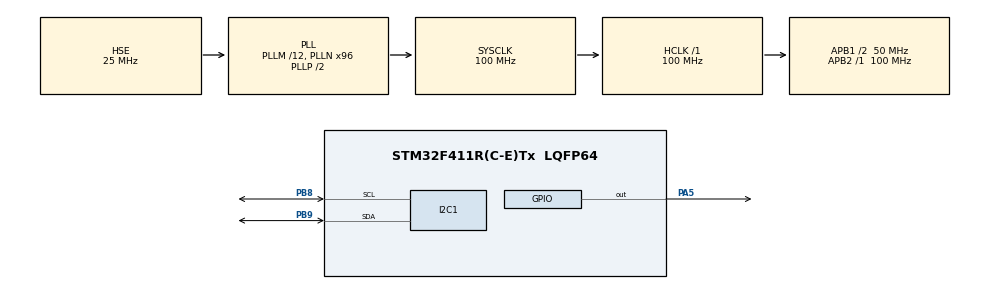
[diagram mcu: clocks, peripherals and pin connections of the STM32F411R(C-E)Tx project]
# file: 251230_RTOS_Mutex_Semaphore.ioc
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FREERTOS.BinarySemaphores01=lcdBinarySem,Dynamic,NULL,Available
FREERTOS.Mutexes01=lcdMutex,Dynamic,NULL,Available
FREERTOS.Tasks01=defaultTask,0,128,StartDefaultTask,Default,NULL,Dynamic,NULL,NULL;myTask02,0,128,StartTask02,Default,NULL,Dynamic,NULL,NULL;myTask03,0,128,StartTask03,Default,NULL,Dynamic,NULL,NULL
FREERTOS.configUSE_NEWLIB_REENTRANT=1
Mcu.Family=STM32F4
Mcu.Name=STM32F411R(C-E)Tx
Mcu.Package=LQFP64
NVIC.PriorityGroup=NVIC_PRIORITYGROUP_4
NVIC.TIM1_TRG_COM_TIM11_IRQn=true\:15\:0\:false\:false\:true\:false\:false\:true\:true
NVIC.TimeBase=TIM1_TRG_COM_TIM11_IRQn
NVIC.TimeBaseIP=TIM11
PA13.Mode=Serial_Wire
PA13.Signal=SYS_JTMS-SWDIO
PA14.Mode=Serial_Wire
PA14.Signal=SYS_JTCK-SWCLK
PA5.Signal=GPIO_Output
PB8.Mode=I2C
PB8.Signal=I2C1_SCL
PB9.Mode=I2C
PB9.Signal=I2C1_SDA
PH0\ -\ OSC_IN.Mode=HSE-External-Oscillator
PH0\ -\ OSC_IN.Signal=RCC_OSC_IN
PH1\ -\ OSC_OUT.Mode=HSE-External-Oscillator
PH1\ -\ OSC_OUT.Signal=RCC_OSC_OUT
ProjectManager.HeapSize=0x200
ProjectManager.StackSize=0x400
ProjectManager.TargetToolchain=STM32CubeIDE
RCC.48MHZClocksFreq_Value=50000000
RCC.AHBFreq_Value=100000000
RCC.APB1CLKDivider=RCC_HCLK_DIV2
RCC.APB1Freq_Value=50000000
RCC.APB1TimFreq_Value=100000000
RCC.APB2Freq_Value=100000000
RCC.APB2TimFreq_Value=100000000
RCC.CortexFreq_Value=100000000
RCC.HCLKFreq_Value=100000000
RCC.HSE_VALUE=25000000
RCC.HSI_VALUE=16000000
RCC.LSE_VALUE=32768
RCC.PLLM=12
RCC.PLLN=96
RCC.PLLSourceVirtual=RCC_PLLSOURCE_HSE
RCC.SYSCLKFreq_VALUE=100000000
RCC.SYSCLKSource=RCC_SYSCLKSOURCE_PLLCLK
RCC.VCOOutputFreq_Value=200000000
VP_FREERTOS_VS_CMSIS_V1.Mode=CMSIS_V1
VP_SYS_VS_tim11.Mode=TIM11
board=custom

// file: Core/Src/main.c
/* USER CODE BEGIN Header */
/**
  ******************************************************************************
  * @file           : main.c
  * @brief          : Main program body
  ******************************************************************************
  * @attention
  *
  * Copyright (c) 2025 STMicroelectronics.
  * All rights reserved.
  *
  * This software is licensed under terms that can be found in the LICENSE file
  * in the root directory of this software component.
  * If no LICENSE file comes with this software, it is provided AS-IS.
  *
  ******************************************************************************
  */
/* USER CODE END Header */
#include "main.h"
#include "cmsis_os.h"
#include "i2c.h"
#include "gpio.h"

void SystemClock_Config(void);
void MX_FREERTOS_Init(void);

int main(void)
{

  /* MCU Configuration--------------------------------------------------------*/

  /* Reset of all peripherals, Initializes the Flash interface and the Systick. */
  HAL_Init();

  /* Configure the system clock */
  SystemClock_Config();

  /* Initialize all configured peripherals */
  MX_GPIO_Init();
  MX_I2C1_Init();

  /* Call init function for freertos objects (in cmsis_os2.c) */
  MX_FREERTOS_Init();

  /* Start scheduler */
  osKernelStart();

  /* We should never get here as control is now taken by the scheduler */

  /* Infinite loop */
  while (1)
  {

  }
}

void SystemClock_Config(void)
{
  RCC_OscInitTypeDef RCC_OscInitStruct = {0};
  RCC_ClkInitTypeDef RCC_ClkInitStruct = {0};

  /** Configure the main internal regulator output voltage
  */
  __HAL_RCC_PWR_CLK_ENABLE();
  __HAL_PWR_VOLTAGESCALING_CONFIG(PWR_REGULATOR_VOLTAGE_SCALE1);

  /** Initializes the RCC Oscillators according to the specified parameters
  * in the RCC_OscInitTypeDef structure.
  */
  RCC_OscInitStruct.OscillatorType = RCC_OSCILLATORTYPE_HSE;
  RCC_OscInitStruct.HSEState = RCC_HSE_ON;
  RCC_OscInitStruct.PLL.PLLState = RCC_PLL_ON;
  RCC_OscInitStruct.PLL.PLLSource = RCC_PLLSOURCE_HSE;
  RCC_OscInitStruct.PLL.PLLM = 12;
  RCC_OscInitStruct.PLL.PLLN = 96;
  RCC_OscInitStruct.PLL.PLLP = RCC_PLLP_DIV2;
  RCC_OscInitStruct.PLL.PLLQ = 4;
  if (HAL_RCC_OscConfig(&RCC_OscInitStruct) != HAL_OK)
  {
    Error_Handler();
  }

  /** Initializes the CPU, AHB and APB buses clocks
  */
  RCC_ClkInitStruct.ClockType = RCC_CLOCKTYPE_HCLK|RCC_CLOCKTYPE_SYSCLK
                              |RCC_CLOCKTYPE_PCLK1|RCC_CLOCKTYPE_PCLK2;
  RCC_ClkInitStruct.SYSCLKSource = RCC_SYSCLKSOURCE_PLLCLK;
  RCC_ClkInitStruct.AHBCLKDivider = RCC_SYSCLK_DIV1;
  RCC_ClkInitStruct.APB1CLKDivider = RCC_HCLK_DIV2;
  RCC_ClkInitStruct.APB2CLKDivider = RCC_HCLK_DIV1;

  if (HAL_RCC_ClockConfig(&RCC_ClkInitStruct, FLASH_LATENCY_3) != HAL_OK)
  {
    Error_Handler();
  }
}

void HAL_TIM_PeriodElapsedCallback(TIM_HandleTypeDef *htim)
{
  if (htim->Instance == TIM11)
  {
    HAL_IncTick();
  }
}

void Error_Handler(void)
{
  __disable_irq();
  while (1)
  {
  }
}

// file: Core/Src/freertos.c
/* USER CODE BEGIN Header */
/**
  ******************************************************************************
  * File Name          : freertos.c
  * Description        : Code for freertos applications
  ******************************************************************************
  * @attention
  *
  * Copyright (c) 2025 STMicroelectronics.
  * All rights reserved.
  *
  * This software is licensed under terms that can be found in the LICENSE file
  * in the root directory of this software component.
  * If no LICENSE file comes with this software, it is provided AS-IS.
  *
  ******************************************************************************
  */
/* USER CODE END Header */

#include "FreeRTOS.h"
#include "task.h"
#include "main.h"
#include "cmsis_os.h"

/* USER CODE BEGIN Includes */
#include <stdio.h>
#include "../driver/lcd/lcd.h"
#include "i2c.h"
#include "queue.h"
/* USER CODE END Includes */

/* USER CODE BEGIN Variables */
que_t que_task2_to_task3;
que_t que_task3_to_task2; // Circular Queue

/* USER CODE END Variables */
osThreadId defaultTaskHandle;
osThreadId myTask02Handle;
osThreadId myTask03Handle;
osMutexId lcdMutexHandle;
osSemaphoreId lcdBinarySemHandle;

void StartDefaultTask(void const * argument);
void StartTask02(void const * argument);
void StartTask03(void const * argument);

void MX_FREERTOS_Init(void); /* (MISRA C 2004 rule 8.1) */

/* GetIdleTaskMemory prototype (linked to static allocation support) */
void vApplicationGetIdleTaskMemory( StaticTask_t **ppxIdleTaskTCBBuffer, StackType_t **ppxIdleTaskStackBuffer, uint32_t *pulIdleTaskStackSize );

/* USER CODE BEGIN GET_IDLE_TASK_MEMORY */
static StaticTask_t xIdleTaskTCBBuffer;
static StackType_t xIdleStack[configMINIMAL_STACK_SIZE];

void vApplicationGetIdleTaskMemory( StaticTask_t **ppxIdleTaskTCBBuffer, StackType_t **ppxIdleTaskStackBuffer, uint32_t *pulIdleTaskStackSize )
{
  *ppxIdleTaskTCBBuffer = &xIdleTaskTCBBuffer;
  *ppxIdleTaskStackBuffer = &xIdleStack[0];
  *pulIdleTaskStackSize = configMINIMAL_STACK_SIZE;
  /* place for user code */
}
/* USER CODE END GET_IDLE_TASK_MEMORY */

void MX_FREERTOS_Init(void) {
  /* USER CODE BEGIN Init */
	Que_Init(&que_task2_to_task3);
	Que_Init(&que_task3_to_task2);
	LCD_Init(&hi2c1);
  /* USER CODE END Init */
  /* Create the mutex(es) */
  /* definition and creation of lcdMutex */
  osMutexDef(lcdMutex);
  lcdMutexHandle = osMutexCreate(osMutex(lcdMutex));

  /* Create the semaphores(s) */
  /* definition and creation of lcdBinarySem */
  osSemaphoreDef(lcdBinarySem);
  lcdBinarySemHandle = osSemaphoreCreate(osSemaphore(lcdBinarySem), 1);

  /* Create the thread(s) */
  /* definition and creation of defaultTask */
  osThreadDef(defaultTask, StartDefaultTask, osPriorityNormal, 0, 128);
  defaultTaskHandle = osThreadCreate(osThread(defaultTask), NULL);

  /* definition and creation of myTask02 */
  osThreadDef(myTask02, StartTask02, osPriorityNormal, 0, 128);
  myTask02Handle = osThreadCreate(osThread(myTask02), NULL);

  /* definition and creation of myTask03 */
  osThreadDef(myTask03, StartTask03, osPriorityNormal, 0, 128);
  myTask03Handle = osThreadCreate(osThread(myTask03), NULL);

}

void StartDefaultTask(void const * argument)
{
  /* USER CODE BEGIN StartDefaultTask */
  /* Infinite loop */
  for(;;)
  {
	  HAL_GPIO_TogglePin(GPIOA, GPIO_PIN_5);
    osDelay(500);
  }
  /* USER CODE END StartDefaultTask */
}

void StartTask02(void const * argument)
{
  /* USER CODE BEGIN StartTask02 */
	char msg[50];
	int count = 0;
	int recv;
  /* Infinite loop */
  for(;;)
  {
	  // Send Data Check
	  Que_Enque(&que_task2_to_task3, count);
	  sprintf(msg, "Task02:%d", count++);
//	  osMutexWait(lcdMutexHandle, osWaitForever);
	  osSemaphoreWait(lcdBinarySemHandle, osWaitForever);
	  LCD_WriteStringXY(0, 0, msg);
	  osSemaphoreRelease(lcdBinarySemHandle);
//	  osMutexRelease(lcdMutexHandle);

	  // Recv Data Check
	  if (!Que_isEmpty(&que_task3_to_task2)) {
		  recv = Que_Deque(&que_task3_to_task2);

		  sprintf(msg, "recv:%d", recv);
		  osSemaphoreWait(lcdBinarySemHandle, osWaitForever);
		  LCD_WriteStringXY(0, 9, msg);
		  osSemaphoreRelease(lcdBinarySemHandle);
	  }
    osDelay(1000);
  }
  /* USER CODE END StartTask02 */
}

void StartTask03(void const * argument)
{
  /* USER CODE BEGIN StartTask03 */
	char msg[50];
	int count = 0;
	int recv;
  /* Infinite loop */
  for(;;)
  {
	  Que_Enque(&que_task3_to_task2, count);

	  sprintf(msg, "Task03:%d", count++);
//	  osMutexWait(lcdMutexHandle, osWaitForever);
	  osSemaphoreWait(lcdBinarySemHandle, osWaitForever);
	  LCD_WriteStringXY(1, 0, msg);
//	  osMutexRelease(lcdMutexHandle);
	  osSemaphoreRelease(lcdBinarySemHandle);

	  if (!Que_isEmpty(&que_task2_to_task3)) {
		  recv = Que_Deque(&que_task2_to_task3);

		  sprintf(msg, "recv:%d", recv);
		  osSemaphoreWait(lcdBinarySemHandle, osWaitForever);
		  LCD_WriteStringXY(1, 9, msg);
		  osSemaphoreRelease(lcdBinarySemHandle);
	  }
    osDelay(1500);
  }
  /* USER CODE END StartTask03 */
}
